# MCU_I3C0_COMMON_0_VBP2APB_WRAP_CORE_VBP_MIPI_I3C_MST register map
Vendor: Texas Instruments
Registers are 32-bit, read-write, reset 0x0 unless marked. A register's access mark holds for its fields unless they carry their own. Offsets are as the file gives them; [hi:lo] are bit positions; {n}, {i} and the like mark numbered series.

## MCU_I3C0_COMMON_0_VBP2APB_WRAP_CORE_VBP_MIPI_I3C_MST (part 2 of 2)
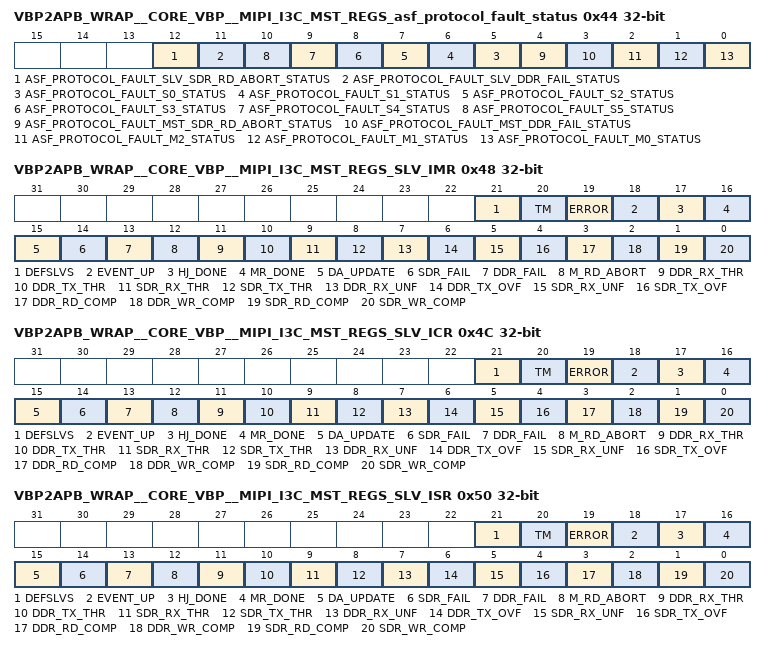
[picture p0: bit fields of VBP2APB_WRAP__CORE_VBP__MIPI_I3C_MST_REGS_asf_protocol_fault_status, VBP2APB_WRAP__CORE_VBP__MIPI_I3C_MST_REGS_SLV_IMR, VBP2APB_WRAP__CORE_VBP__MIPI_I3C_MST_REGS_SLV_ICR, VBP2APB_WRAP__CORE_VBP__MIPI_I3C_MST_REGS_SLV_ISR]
0x44 VBP2APB_WRAP__CORE_VBP__MIPI_I3C_MST_REGS_asf_protocol_fault_status access not given
  [12] ASF_PROTOCOL_FAULT_SLV_SDR_RD_ABORT_STATUS — Status bit for slv_sdr_rd_abort protocol fault. (access R/W1TC)
  [11] ASF_PROTOCOL_FAULT_SLV_DDR_FAIL_STATUS — Status bit for slv_ddr_fail protocol fault. (access R/W1TC)
  [n+5] ASF_PROTOCOL_FAULT_S{n}_STATUS (n=0..5) — Status bit for s{n} protocol fault. (access R/W1TC)
  [4] ASF_PROTOCOL_FAULT_MST_SDR_RD_ABORT_STATUS — Status bit for mst_sdr_rd_abort protocol fault. (access R/W1TC)
  [3] ASF_PROTOCOL_FAULT_MST_DDR_FAIL_STATUS — Status bit for mst_ddr_fail protocol fault. (access R/W1TC)
  [2] ASF_PROTOCOL_FAULT_M2_STATUS — Status bit for m2 protocol fault. (access R/W1TC)
  [1] ASF_PROTOCOL_FAULT_M1_STATUS — Status bit for m1 protocol fault. (access R/W1TC)
  [0] ASF_PROTOCOL_FAULT_M0_STATUS — Status bit for m0 protocol fault. (access R/W1TC)
0x48 VBP2APB_WRAP__CORE_VBP__MIPI_I3C_MST_REGS_SLV_IMR ro
  [21] DEFSLVS — DEFSLVS interrupt Mask.
  [20] TM — TM interrupt Mask.
  [19] ERROR — ERROR interrupt Mask.
  [18] EVENT_UP — EVENT_UP interrupt Mask.
  [17] HJ_DONE — HJ_DONE interrupt Mask.
  [16] MR_DONE — MR_DONE interrupt Mask.
  [15] DA_UPDATE — DA_UPDATE interrupt Mask.
  [14] SDR_FAIL — SDR_FAIL interrupt Mask
  [13] DDR_FAIL — DDR_FAIL interrupt Mask
  [12] M_RD_ABORT — M_RD_ABORT interrupt Mask.
  [11] DDR_RX_THR — DDR_RX_THR interrupt Mask.
  [10] DDR_TX_THR — DDR_TX_THR interrupt Mask.
  [9] SDR_RX_THR — SDR_RX_THR interrupt Mask.
  [8] SDR_TX_THR — SDR_TX_THR interrupt Mask.
  [7] DDR_RX_UNF — DDR_RX_UNF interrupt Mask.
  [6] DDR_TX_OVF — DDR_TX_OVF interrupt Mask.
  [5] SDR_RX_UNF — SDR_RX_UNF interrupt Mask.
  [4] SDR_TX_OVF — SDR_TX_OVF interrupt Mask.
  [3] DDR_RD_COMP — DDR_RD_COMP interrupt Mask.
  [2] DDR_WR_COMP — DDR_WR_COMP interrupt Mask.
  [1] SDR_RD_COMP — SDR_RD_COMP interrupt Mask.
  [0] SDR_WR_COMP — SDR_WR_COMP interrupt Mask.
0x4C VBP2APB_WRAP__CORE_VBP__MIPI_I3C_MST_REGS_SLV_ICR wo
  [21] DEFSLVS — DEFSLVS interrupt Clear.
  [20] TM — TM interrupt Clear.
  [19] ERROR — ERROR interrupt Clear.
  [18] EVENT_UP — EVENT_UP interrupt Clear.
  [17] HJ_DONE — HJ_DONE interrupt Clear.
  [16] MR_DONE — MR_DONE interrupt Clear.
  [15] DA_UPDATE — DA_UPDATE interrupt Clear.
  [14] SDR_FAIL — SDR_FAIL interrupt Clear.
  [13] DDR_FAIL — DDR_FAIL interrupt Clear.
  [12] M_RD_ABORT — M_RD_ABORT interrupt Clear.
  [11] DDR_RX_THR — DDR_RX_THR interrupt Clear.
  [10] DDR_TX_THR — DDR_TX_THR interrupt Clear.
  [9] SDR_RX_THR — SDR_RX_THR interrupt Clear.
  [8] SDR_TX_THR — SDR_TX_THR interrupt Clear.
  [7] DDR_RX_UNF — DDR_RX_UNF interrupt Clear.
  [6] DDR_TX_OVF — DDR_TX_OVF interrupt Clear.
  [5] SDR_RX_UNF — SDR_RX_UNF interrupt Clear.
  [4] SDR_TX_OVF — SDR_TX_OVF interrupt Clear.
  [3] DDR_RD_COMP — DDR_RD_COMP interrupt Clear.
  [2] DDR_WR_COMP — DDR_WR_COMP interrupt Clear.
  [1] SDR_RD_COMP — SDR_RD_COMP interrupt Clear.
  [0] SDR_WR_COMP — SDR_WR_COMP interrupt Clear.
0x50 VBP2APB_WRAP__CORE_VBP__MIPI_I3C_MST_REGS_SLV_ISR ro
  [21] DEFSLVS — This interrupt is triggered whenever I3C-Slave DEFSLVS CCC command is received.
  [20] TM — This interrupt is triggered whenever I3C-Slave is not in Test Mode and ENTTM CCC requests to enter general Test Mode.
  [19] ERROR — This event is triggered whenever SDR Error is detected - applicable for S0, S1, S2, S4 and S5 Errors from MIPI spec.
  [18] EVENT_UP — This event is triggered whenever DISEC CCC or ENEC CCC is received.
  [17] HJ_DONE — This event is triggered whenever Hot-Join request is completed.
  [16] MR_DONE — This event is triggered whenever Mastership Request is completed.
  [15] DA_UPDATE — This event is triggered whenever Dynamic Address of the device has been updated.
  [14] SDR_FAIL — This event is triggered whenever fail event during SDR transfer is detected [applicable for Private Write transfers only].
  [13] DDR_FAIL — This event is triggered whenever fail event during DDR transfer is detected.
  [12] M_RD_ABORT — Read Transfer Aborted by Master.
  [11] DDR_RX_THR — Slave DDR Rx DATA Buffer Threshold. It is set when the number of words in the Slave DDR Rx DATA Buffer reaches value programmed in SLV_DDR_TX_RX_THR_CTRL.slv_ddr_rx_thr field.
  [10] DDR_TX_THR — Slave DDR Tx DATA Buffer Threshold. It is set when the number of words in the Slave DDR Tx DATA Buffer reaches value programmed in SLV_DDR_TX_RX_THR_CTRL.slv_ddr_tx_thr field.
  [9] SDR_RX_THR — Rx DATA Buffer Threshold. It is set when the number of bytes in the Rx DATA Buffer reaches value programmed in TX_RX_THR_CTRL.rx_thr field.
  [8] SDR_TX_THR — Tx DATA Buffer Threshold. It is set when the number of bytes in the Tx DATA Buffer reaches value programmed in TX_RX_THR_CTRL.tx_thr field.
  [7] DDR_RX_UNF — Slave DDR Rx DATA Buffer Underflow. Set if host attempts to read from the empty Slave Rx DATA Buffer.
  [6] DDR_TX_OVF — Slave DDR Tx DATA Buffer Overflow. Set if host attepmts to write to Slvave DDR Tx DATA Buffer which is already full.
  [5] SDR_RX_UNF — Rx DATA Buffer Underflow. Set if host attempts to read from the empty Rx DATA Buffer.
  [4] SDR_TX_OVF — Tx DATA Buffer Overflow. Set if host attempts to write to Tx DATA Buffer which is already full.
  [3] DDR_RD_COMP — This bit is set whenever the Slave terminates the DDR Read transfer.
  [2] DDR_WR_COMP — This bit is set whenever the Master terminates the DDR Write transfer.
  [1] SDR_RD_COMP — This bit is set whenever the Slave terminates the SDR Private Read transfer.
  [0] SDR_WR_COMP — This bit is set whenever the Master terminates the SDR Private Write transfer.
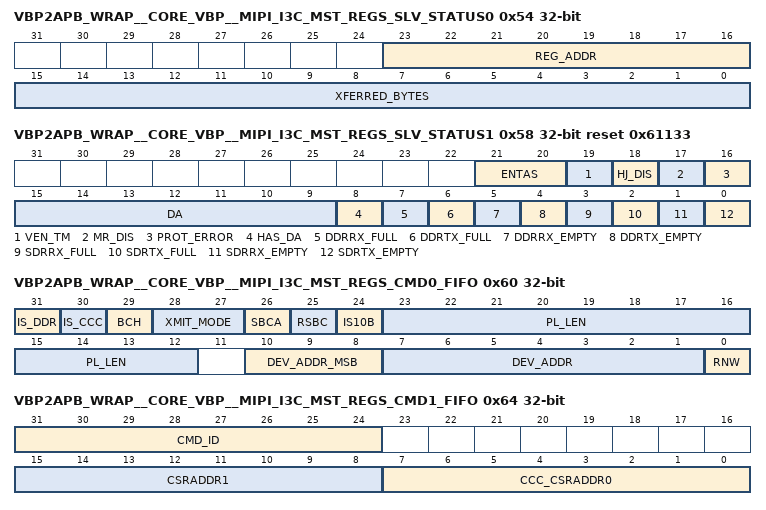
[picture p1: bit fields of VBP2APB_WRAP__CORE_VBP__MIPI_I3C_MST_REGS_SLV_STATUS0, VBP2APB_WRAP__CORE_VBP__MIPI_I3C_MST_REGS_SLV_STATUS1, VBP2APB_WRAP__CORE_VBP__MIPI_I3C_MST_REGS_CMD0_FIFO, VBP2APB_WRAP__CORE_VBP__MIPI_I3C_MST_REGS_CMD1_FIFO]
0x54 VBP2APB_WRAP__CORE_VBP__MIPI_I3C_MST_REGS_SLV_STATUS0 ro
  [23:16] REG_ADDR — Private Read/Write Address.
  [15:0] XFERRED_BYTES — Number of transferred bytes in SDR transactions.
0x58 VBP2APB_WRAP__CORE_VBP__MIPI_I3C_MST_REGS_SLV_STATUS1 ro reset 0x61133
  [21:20] ENTAS — Bits that indicate current Activity State. It is updated based on ENTASx CCC [broadcast or direct], by default is set to 2'b00.
  [19] VEN_TM — Vendor Test Mode. This bit is set whenever ENTTM CCC requests to enter general Test Mode. It remains HIGH until reception of another ENTTM CCC with different value.
  [18] HJ_DIS — Hot-Join Request is Disabled. This bit is set whenever HJ request is disabled by Current I3C-Master using DISEC CCC.
  [17] MR_DIS — Mastership Request is Disabled. This bit is set whenever MR request is disabled by Current I3C-Master using DISEC CCC.
  [16] PROT_ERROR — Protocol Error Condition Indicator. This bit is set whenever SDR error condition is detected by I3C-Master operating in Slave mode. It remains High until detection of recovery pattern.
  [15:9] DA — Current Slave Dynamic Address. Irrelevant if SLV_STATUS1.has_da bit is Low.
  [8] HAS_DA — This bit is set whenever Slave has Dynamic Address assigned. Tied HIGH when controller operates as Main Master device class.
  [7] DDRRX_FULL — This bit is set whenever Slave DDR Rx DATA Buffer is full.
  [6] DDRTX_FULL — This bit is set whenever Slave DDR Tx DATA Buffer is full.
  [5] DDRRX_EMPTY — This bit is set whenever Slave DDR Rx DATA Buffer is empty.
  [4] DDRTX_EMPTY — This bit is set whenever Slave DDR Tx DATA Buffer is empty.
  [3] SDRRX_FULL — This bit is set whenever Rx DATA Buffer is full.
  [2] SDRTX_FULL — This bit is set whenever Tx DATA Buffer is full.
  [1] SDRRX_EMPTY — This bit is set whenever Rx DATA Buffer is empty.
  [0] SDRTX_EMPTY — This bit is set whenever Tx DATA Buffer is empty.
0x60 VBP2APB_WRAP__CORE_VBP__MIPI_I3C_MST_REGS_CMD0_FIFO wo
  [31] IS_DDR — IS_DDR - DDR command. Enables DDR mode of transfer. 0 - SDR mode 1 - DDR mode, note that ENTHDR-DDR CCC should precede any commands with DDR mode enabled.
  [30] IS_CCC — IsCCC. Denotes whether it is a CCC or generic command. 0 - generic command 1 - CCC command
  [29] BCH — BCH - Broadcast Header. Defines whether command will includes broadcast address header [0x7E] or not. Implicitly set for CCC commands. 0 - broadcast header disabled 1 - broadcast header enabled
  [28:27] XMIT_MODE — Defines transfer modes for I3C SDR private read/write commands [not CCC], the following options are available: 00 - burst [byte-by-byte] transfer with static register sub-address. Send static sub-address followed by data bytes only. 01 - single data byte transfers with auto incremented register sub-addressing. Each data byte is followed by repeated start condition and slave's sub-address is inremented explicitly. 10 - single data byte transfers without auto incremented register sub-addressing. Each data byte is followed by repeated start condition, register sub-address as in CMD descriptor for all transactions. 11 - burst [byte-by-byte] transfer without register sub-addressing, i.e. first data byte after the DA/SA is payload byte acquired from Tx DATA buffer.
  [26] SBCA — SBCA - Sixteen Bits CSR Addressing. Defines the CSR addressing mode for I3C private commands only. 0 - normal CSR addressing mode [8-bit] - ADDR0_7 - ADDR0_0 1 - extended CSR addressing mode [16-bit] - ADDR0_7 - ADDR0_0 and ADDR1_7 - ADDR1_0
  [25] RSBC — RSBC - Repeated Start Between Commands. When this bit is set then between commands he repeated start condition is issued instead stop condition. It is only applicable when there is more than one command is in the command queue and next command is for Slave device of same type. The stop condition will be generated regardless of RSCB bit value for the following scenarios: - current command is the last command in the command queue - next command has invalid DA/SA - immediate command comes through
  [24] IS10B — Is10B - Normal/Extended Address. Defines the addressing mode, applicable only for legacy I2C messaging. 0 - normal addressing mode [7-bit] - ID6-ID0 1 - extended addressing mode [10-bit] - ID10B2-ID10B0 and ID6-ID0
  [23:12] PL_LEN — PL_LEN - Payload Length, defines number of bytes to be sent for particular CCC or generic R/Q command. Supports up to 4095 bytes.
  [10:8] DEV_ADDR_MSB — DEV_ADDR_MSB - legacy I2C Extended Address. The 3 MSB bits of legacy I2C 10-bit address. Applicable only if Is_10B is set for I2C legacy transfers.
  [7:1] DEV_ADDR — DEV_ADDR - Static/Dynamic slave Address. Correspond to a given slave Dynamic Address and Static Address. For CCC is applicable only when it is direct CCC command. For broadcast CCC this field is ignored.
  [0] RNW — RnW - Read no Write. Defines the direction of transfer, for broadcast CCC this field is ignored. 0 - Write Transfer 1 - Read Transfer
0x64 VBP2APB_WRAP__CORE_VBP__MIPI_I3C_MST_REGS_CMD1_FIFO wo
  [31:24] CMD_ID — CMD_ID - command identifier.
  [15:8] CSRADDR1 — CSR ADDR1 - second byte of the CSR address in 16-bit addressing mode. Applicable only when 16-bit addressing mode is used and for private commands [non CCC commands].
  [7:0] CCC_CSRADDR0 — CCC/CSR ADDR0 - CCC or CSR Address. Meaning of this field depends on bit 30 [IsCCC] of Command Word0. - When is_ccc is set to '0' then this field holds address of slave CSR. When 16-bit addressing is used, then it is the first byte of the CSR address. - When is ccc is set to '1' then this field holds code of CCC.
0x68 VBP2APB_WRAP__CORE_VBP__MIPI_I3C_MST_REGS_TX_FIFO wo
  [31:0] DATA — Tx DATA payload.
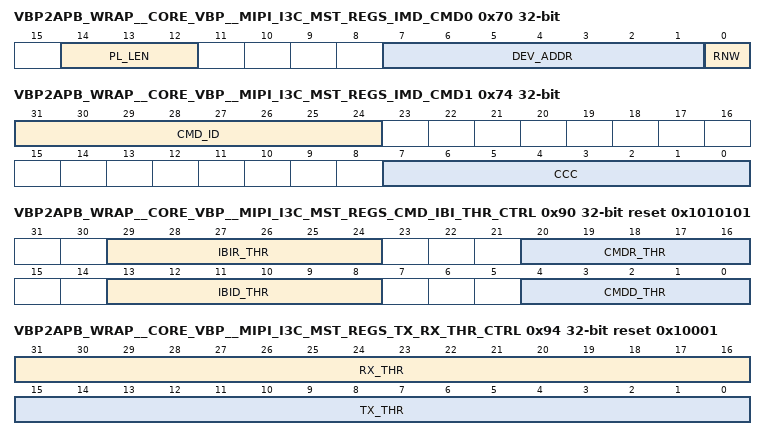
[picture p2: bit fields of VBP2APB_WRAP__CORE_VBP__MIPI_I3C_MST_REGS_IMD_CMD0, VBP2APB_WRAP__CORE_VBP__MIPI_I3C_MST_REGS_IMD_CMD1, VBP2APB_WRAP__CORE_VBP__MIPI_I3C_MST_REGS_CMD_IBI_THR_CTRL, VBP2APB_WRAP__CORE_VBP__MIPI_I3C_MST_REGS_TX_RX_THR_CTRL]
0x70 VBP2APB_WRAP__CORE_VBP__MIPI_I3C_MST_REGS_IMD_CMD0 wo
  [14:12] PL_LEN — PL_LEN - Payload Length, defines number of bytes to be send for particular CCC or generic R/W command. Supports up to 4 bytes.
  [7:1] DEV_ADDR — DEV_ADDR - Static/Dynamic slave Address. Correspond to a given slave Dynamic Address and Static Address. For CCC is applicable only when it is direct CCC command. For broadcast CCC this field is ignored.
  [0] RNW — RnW - Read not Write. Defines the direction of transfer, for broadcast CCC this field is ignored. 0 - Write Transfer 1 - Read Transfer
0x74 VBP2APB_WRAP__CORE_VBP__MIPI_I3C_MST_REGS_IMD_CMD1 wo
  [31:24] CMD_ID — CMD_ID - command identifier.
  [7:0] CCC — CCC Code - field holds code of CCC message.
0x78 VBP2APB_WRAP__CORE_VBP__MIPI_I3C_MST_REGS_IMD_DATA
  [31:0] DATA — Tx DATA payload [it's not a FIFO, supports up to 4 bytes only].
0x80 VBP2APB_WRAP__CORE_VBP__MIPI_I3C_MST_REGS_RX_FIFO ro
  [31:0] DATA — Rx DATA payload.
0x84 VBP2APB_WRAP__CORE_VBP__MIPI_I3C_MST_REGS_IBI_DATA_FIFO ro
  [31:0] DATA — IBI DATA payload.
0x88 VBP2APB_WRAP__CORE_VBP__MIPI_I3C_MST_REGS_SLV_DDR_TX_FIFO wo
  [19:0] DDR_SLAVE_TX_DATA_FIFO — DDR Tx DATA payload [with meta-data, e.g. preamble/parity].
0x8C VBP2APB_WRAP__CORE_VBP__MIPI_I3C_MST_REGS_SLV_DDR_RX_FIFO ro
  [19:0] DDR_SLAVE_RX_DATA_FIFO — DDR Rx DATA payload [with meta-data, e.g. preamble/parity].
0x90 VBP2APB_WRAP__CORE_VBP__MIPI_I3C_MST_REGS_CMD_IBI_THR_CTRL reset 0x1010101
  [29:24] IBIR_THR — Threshold configuration value for IBI Response Queue.
  [20:16] CMDR_THR — Threshold configuration value for Command Response Queue.
  [13:8] IBID_THR — Threshold configuration value for IBI DATA Buffer.
  [4:0] CMDD_THR — Threshold configuration value for Command Queue.
0x94 VBP2APB_WRAP__CORE_VBP__MIPI_I3C_MST_REGS_TX_RX_THR_CTRL reset 0x10001
  [31:16] RX_THR — Threshold configuration value for Rx Data memory block
  [15:0] TX_THR — Threshold configuration value for Tx Data memory block
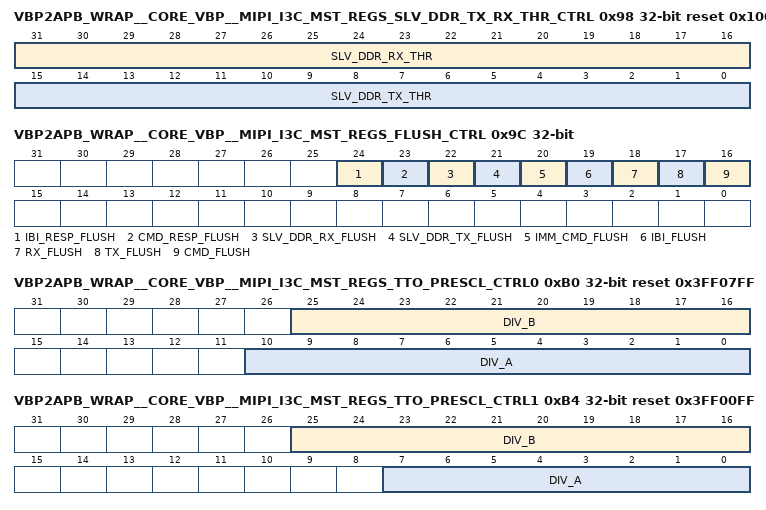
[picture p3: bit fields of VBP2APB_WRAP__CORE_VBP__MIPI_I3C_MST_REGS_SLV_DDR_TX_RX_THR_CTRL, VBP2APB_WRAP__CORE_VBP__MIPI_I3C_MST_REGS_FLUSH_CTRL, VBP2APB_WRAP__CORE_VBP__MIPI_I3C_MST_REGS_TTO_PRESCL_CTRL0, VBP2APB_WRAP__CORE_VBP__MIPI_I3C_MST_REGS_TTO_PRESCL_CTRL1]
0x98 VBP2APB_WRAP__CORE_VBP__MIPI_I3C_MST_REGS_SLV_DDR_TX_RX_THR_CTRL reset 0x10001
  [31:16] SLV_DDR_RX_THR — Threshold configuration value for Slave DDR Rx DATA buffer.
  [15:0] SLV_DDR_TX_THR — Threshold configuration value for Slave DDR Tx DATA buffer.
0x9C VBP2APB_WRAP__CORE_VBP__MIPI_I3C_MST_REGS_FLUSH_CTRL wo
  [24] IBI_RESP_FLUSH — When asserted while controller is disabled, the IBI Response Queue read/write pointers will be set to 0, effectively makes the buffer empty. Self-cleared control bit.
  [23] CMD_RESP_FLUSH — When asserted while controller is disabled, the Command Response Queue read/write pointers will be set to 0, effectively makes the buffer empty. Self-cleared control bit.
  [22] SLV_DDR_RX_FLUSH — When asserted while controller is disabled, the Slave DDR Rx DATA Buffer read/write pointers will be set to 0, effectively makes the buffer empty. Self-cleared control bit.
  [21] SLV_DDR_TX_FLUSH — When asserted while controller is disabled, the Slave DDR Tx DATA Buffer read/write pointers will be set to 0, effectively makes the buffer empty. Self-cleared control bit.
  [20] IMM_CMD_FLUSH — When asserted while controller is disabled, the Immediate Commadn/DATA registers will be cleared and their empty flag will be asserted. Self-cleared control bit.
  [19] IBI_FLUSH — When asserted while controller is disabled, the IBI DATA Buffer read/write pointers will be set to 0, effectively makes the buffer empty. Self-cleared control bit.
  [18] RX_FLUSH — When asserted while controller is disabled, the Rx DATA Buffer read/write pointers will be set to 0, effectively makes the buffer empty. Self-cleared control bit.. Self-cleared control bit.
  [17] TX_FLUSH — When asserted while controller is disabled, the Tx DATA Buffer read/write pointers will be set to 0, effectively makes the buffer empty. Self-cleared control bit.
  [16] CMD_FLUSH — When asserted while controller is disabled, the Command Buffer read/write pointers will be set to 0, effectively makes the buffer empty. Self-cleared control bit.
0xB0 VBP2APB_WRAP__CORE_VBP__MIPI_I3C_MST_REGS_TTO_PRESCL_CTRL0 reset 0x3FF07FF
  [25:16] DIV_B — Divider B
  [10:0] DIV_A — Divider A
0xB4 VBP2APB_WRAP__CORE_VBP__MIPI_I3C_MST_REGS_TTO_PRESCL_CTRL1 reset 0x3FF00FF
  [25:16] DIV_B — Divider B
  [7:0] DIV_A — Divider A
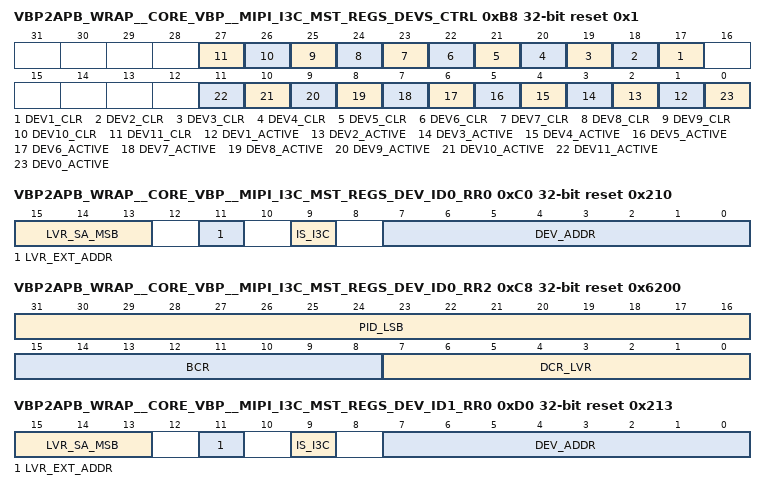
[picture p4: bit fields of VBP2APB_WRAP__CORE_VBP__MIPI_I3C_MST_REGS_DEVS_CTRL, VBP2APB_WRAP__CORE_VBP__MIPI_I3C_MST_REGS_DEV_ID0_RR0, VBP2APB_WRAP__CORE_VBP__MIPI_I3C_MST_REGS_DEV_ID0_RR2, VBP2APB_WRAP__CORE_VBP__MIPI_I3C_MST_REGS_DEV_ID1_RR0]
0xB8 VBP2APB_WRAP__CORE_VBP__MIPI_I3C_MST_REGS_DEVS_CTRL access per field reset 0x1
  [n+16] DEV{n}_CLR wo (n=1..11) — Clear contents of DevID{n} retaining registers. Self-cleared bit.
  [n] DEV{n}_ACTIVE rw (n=1..11) — DevID{n} is active - has either valid DA or SA.
  [0] DEV0_ACTIVE ro — DevID0 is active - has either valid DA or SA.
0xC0 VBP2APB_WRAP__CORE_VBP__MIPI_I3C_MST_REGS_DEV_ID0_RR0 access per field reset 0x210
  [15:13] LVR_SA_MSB rw — MSB bits of Legacy I2C Device with 10-bit addressing.
  [11] LVR_EXT_ADDR rw — Device 0 Address mode used: 0 - 7-bit addressing - applicable for I3C and I2C devices. 1 - 10-bit addressing - applicable only for I2C devices with 10-bit extended address. NOTE: Invalid setting when Device0_RR0.is_i3c=1
  [9] IS_I3C ro — Device 0 I3C mode Operation 1 Yes 0 No
  [7:0] DEV_ADDR rw — Device 0 Slave Dynamic [Static/Legacy] Address bits 7:1 bit 0 - parity XOR check -> ~XOR[dev_addr[7:1]].
0xC4 VBP2APB_WRAP__CORE_VBP__MIPI_I3C_MST_REGS_DEV_ID0_RR1 reset 0x2040000
  [31:0] PID_MSB — Device 0 48 to 16 Dev ID bits
0xC8 VBP2APB_WRAP__CORE_VBP__MIPI_I3C_MST_REGS_DEV_ID0_RR2 reset 0x6200
  [31:16] PID_LSB — Device 0 15 to 0 Dev ID bits
  [15:8] BCR — Device 0 BCR register
  [7:0] DCR_LVR — Device 0 DCR [if I3C device] or LVR [if I2C device] register Decoding if used as DCR: Bits[7:0]: 255 available codes for describing the type of sensor, or Device; Decoding if used as LVR: Bits [7:4]: Device 0 LVR Code: 15 available codes for describing the Device capabilities and function on the sensors' system Bits [3:3]: Device 0 LVR Slave operation mode: 1'b0 FM mode 1'b1 FM+ mode Bits [2:0]: Device 0 LVR Index: 3'b000 Index 0 3'b001 Index 1 3'b010 Index 2 3'b011 Index 3 [Reserved] 3'b100 Index 4 [Reserved] 3'b101 Index 5 [Reserved] 3'b110 Index 6 [Reserved] 3'b111 Index 7 [Reserved]
0xD0 VBP2APB_WRAP__CORE_VBP__MIPI_I3C_MST_REGS_DEV_ID1_RR0 reset 0x213
  [15:13] LVR_SA_MSB — MSB bits of Legacy I2C Device with 10-bit addressing.
  [11] LVR_EXT_ADDR — Device 1 Address mode used: 0 - 7-bit addressing - applicable for I3C and I2C devices. 1 - 10-bit addressing - applicable only for I2C devices with 10-bit extended address. NOTE: Invalid setting when Device1_RR0.is_i3c=1
  [9] IS_I3C — Device 1 I3C mode Operation 1 Yes 0 No
  [7:0] DEV_ADDR — Device 1 Slave Dynamic [Static/Legacy] Address bits 7:1 bit 0 - parity XOR check -> ~XOR[dev_addr[7:1]].
{0xC4+0x10*i} VBP2APB_WRAP__CORE_VBP__MIPI_I3C_MST_REGS_DEV_ID{i}_RR1 (i=1..11)
  [31:0] PID_MSB — Device {i} 48 to 16 Dev ID bits
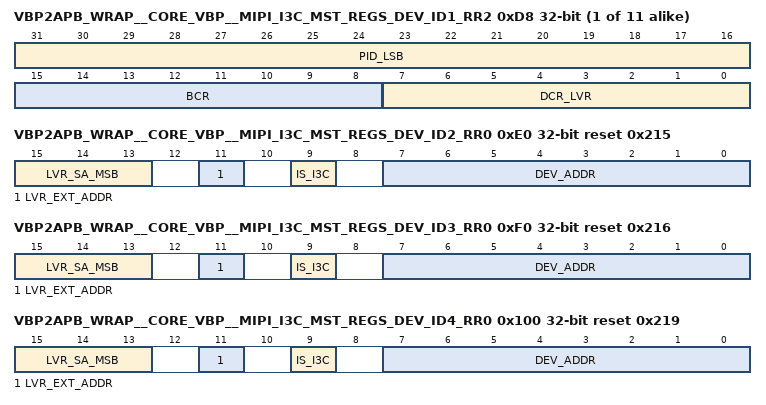
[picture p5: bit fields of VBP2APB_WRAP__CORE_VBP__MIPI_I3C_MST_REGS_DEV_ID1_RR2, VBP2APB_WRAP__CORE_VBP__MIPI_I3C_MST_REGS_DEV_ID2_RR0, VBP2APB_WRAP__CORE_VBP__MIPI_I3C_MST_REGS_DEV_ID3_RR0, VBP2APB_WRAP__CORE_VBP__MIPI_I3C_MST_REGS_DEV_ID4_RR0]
{0xC8+0x10*i} VBP2APB_WRAP__CORE_VBP__MIPI_I3C_MST_REGS_DEV_ID{i}_RR2 (i=1..11)
  [31:16] PID_LSB — Device {i} 15 to 0 Dev ID bits
  [15:8] BCR — Device {i} BCR register
  [7:0] DCR_LVR — Device {i} DCR [if I3C device] or LVR [if I2C device] register Decoding if used as DCR: Bits[7:0]: 255 available codes for describing the type of sensor, or Device; Decoding if used as LVR: Bits [7:4]: Device {i} LVR Code: 15 available codes for describing the Device capabilities and function on the sensors' system Bits [3:3]: Device {i} LVR Slave operation mode: 1'b0 FM mode 1'b1 FM+ mode Bits [2:0]: Device {i} LVR Index: 3'b000 Index 0 3'b001 Index 1 3'b010 Index 2 3'b011 Index 3 [Reserved] 3'b100 Index 4 [Reserved] 3'b101 Index 5 [Reserved] 3'b110 Index 6 [Reserved] 3'b111 Index 7 [Reserved]
0xE0 VBP2APB_WRAP__CORE_VBP__MIPI_I3C_MST_REGS_DEV_ID2_RR0 reset 0x215
  [15:13] LVR_SA_MSB — MSB bits of Legacy I2C Device with 10-bit addressing.
  [11] LVR_EXT_ADDR — Device 2 Address mode used: 0 - 7-bit addressing - applicable for I3C and I2C devices. 1 - 10-bit addressing - applicable only for I2C devices with 10-bit extended address. NOTE: Invalid setting when Device2_RR0.is_i3c=1
  [9] IS_I3C — Device 2 I3C mode Operation 1 Yes 0 No
  [7:0] DEV_ADDR — Device 2 Slave Dynamic [Static/Legacy] Address bits 7:1 bit 0 - parity XOR check -> ~XOR[dev_addr[7:1]].
0xF0 VBP2APB_WRAP__CORE_VBP__MIPI_I3C_MST_REGS_DEV_ID3_RR0 reset 0x216
  [15:13] LVR_SA_MSB — MSB bits of Legacy I2C Device with 10-bit addressing.
  [11] LVR_EXT_ADDR — Device 3 Address mode used: 0 - 7-bit addressing - applicable for I3C and I2C devices. 1 - 10-bit addressing - applicable only for I2C devices with 10-bit extended address. NOTE: Invalid setting when Device3_RR0.is_i3c=1
  [9] IS_I3C — Device 3 I3C mode Operation 1 Yes 0 No
  [7:0] DEV_ADDR — Device 3 Slave Dynamic [Static/Legacy] Address bits 7:1 bit 0 - parity XOR check -> ~XOR[dev_addr[7:1]].
0x100 VBP2APB_WRAP__CORE_VBP__MIPI_I3C_MST_REGS_DEV_ID4_RR0 reset 0x219
  [15:13] LVR_SA_MSB — MSB bits of Legacy I2C Device with 10-bit addressing.
  [11] LVR_EXT_ADDR — Device 4 Address mode used: 0 - 7-bit addressing - applicable for I3C and I2C devices. 1 - 10-bit addressing - applicable only for I2C devices with 10-bit extended address. NOTE: Invalid setting when Device4_RR0.is_i3c=1
  [9] IS_I3C — Device 4 I3C mode Operation 1 Yes 0 No
  [7:0] DEV_ADDR — Device 4 Slave Dynamic [Static/Legacy] Address bits 7:1 bit 0 - parity XOR check -> ~XOR[dev_addr[7:1]].
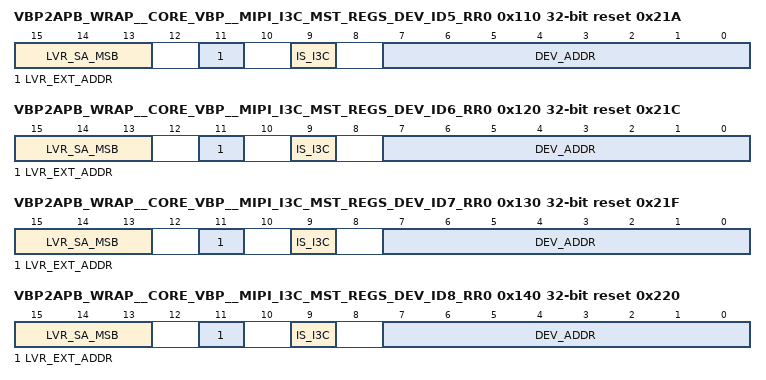
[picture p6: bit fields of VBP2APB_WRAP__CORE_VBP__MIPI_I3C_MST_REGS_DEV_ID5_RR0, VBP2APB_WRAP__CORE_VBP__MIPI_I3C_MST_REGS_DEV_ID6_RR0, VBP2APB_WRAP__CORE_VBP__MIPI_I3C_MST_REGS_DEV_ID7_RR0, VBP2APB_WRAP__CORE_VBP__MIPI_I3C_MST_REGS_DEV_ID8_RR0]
0x110 VBP2APB_WRAP__CORE_VBP__MIPI_I3C_MST_REGS_DEV_ID5_RR0 reset 0x21A
  [15:13] LVR_SA_MSB — MSB bits of Legacy I2C Device with 10-bit addressing.
  [11] LVR_EXT_ADDR — Device 5 Address mode used: 0 - 7-bit addressing - applicable for I3C and I2C devices. 1 - 10-bit addressing - applicable only for I2C devices with 10-bit extended address. NOTE: Invalid setting when Device5_RR0.is_i3c=1
  [9] IS_I3C — Device 5 I3C mode Operation 1 Yes 0 No
  [7:0] DEV_ADDR — Device 5 Slave Dynamic [Static/Legacy] Address bits 7:1 bit 0 - parity XOR check -> ~XOR[dev_addr[7:1]].
0x120 VBP2APB_WRAP__CORE_VBP__MIPI_I3C_MST_REGS_DEV_ID6_RR0 reset 0x21C
  [15:13] LVR_SA_MSB — MSB bits of Legacy I2C Device with 10-bit addressing.
  [11] LVR_EXT_ADDR — Device 6 Address mode used: 0 - 7-bit addressing - applicable for I3C and I2C devices. 1 - 10-bit addressing - applicable only for I2C devices with 10-bit extended address. NOTE: Invalid setting when Device6_RR0.is_i3c=1
  [9] IS_I3C — Device 6 I3C mode Operation 1 Yes 0 No
  [7:0] DEV_ADDR — Device 6 Slave Dynamic [Static/Legacy] Address bits 7:1 bit 0 - parity XOR check -> ~XOR[dev_addr[7:1]].
0x130 VBP2APB_WRAP__CORE_VBP__MIPI_I3C_MST_REGS_DEV_ID7_RR0 reset 0x21F
  [15:13] LVR_SA_MSB — MSB bits of Legacy I2C Device with 10-bit addressing.
  [11] LVR_EXT_ADDR — Device 7 Address mode used: 0 - 7-bit addressing - applicable for I3C and I2C devices. 1 - 10-bit addressing - applicable only for I2C devices with 10-bit extended address. NOTE: Invalid setting when Device7_RR0.is_i3c=1
  [9] IS_I3C — Device 7 I3C mode Operation 1 Yes 0 No
  [7:0] DEV_ADDR — Device 7 Slave Dynamic [Static/Legacy] Address bits 7:1 bit 0 - parity XOR check -> ~XOR[dev_addr[7:1]].
0x140 VBP2APB_WRAP__CORE_VBP__MIPI_I3C_MST_REGS_DEV_ID8_RR0 reset 0x220
  [15:13] LVR_SA_MSB — MSB bits of Legacy I2C Device with 10-bit addressing.
  [11] LVR_EXT_ADDR — Device 8 Address mode used: 0 - 7-bit addressing - applicable for I3C and I2C devices. 1 - 10-bit addressing - applicable only for I2C devices with 10-bit extended address. NOTE: Invalid setting when Device8_RR0.is_i3c=1
  [9] IS_I3C — Device 8 I3C mode Operation 1 Yes 0 No
  [7:0] DEV_ADDR — Device 8 Slave Dynamic [Static/Legacy] Address bits 7:1 bit 0 - parity XOR check -> ~XOR[dev_addr[7:1]].
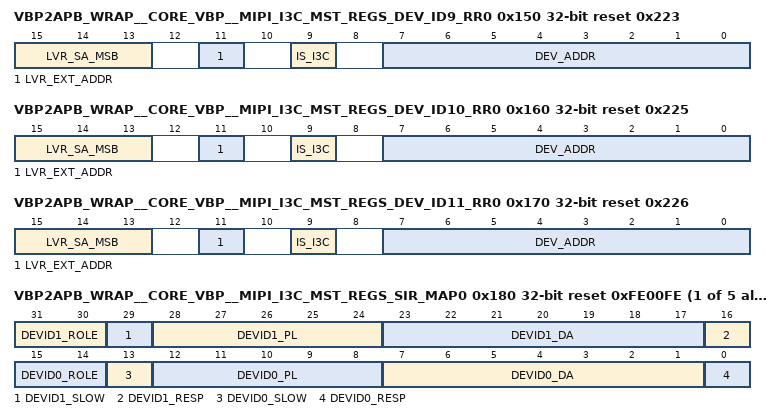
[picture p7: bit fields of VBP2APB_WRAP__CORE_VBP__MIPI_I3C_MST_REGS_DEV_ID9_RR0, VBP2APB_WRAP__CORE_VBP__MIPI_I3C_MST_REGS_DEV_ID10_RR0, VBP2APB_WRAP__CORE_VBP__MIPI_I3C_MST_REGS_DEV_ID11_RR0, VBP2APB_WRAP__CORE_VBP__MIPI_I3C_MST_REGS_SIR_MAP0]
0x150 VBP2APB_WRAP__CORE_VBP__MIPI_I3C_MST_REGS_DEV_ID9_RR0 reset 0x223
  [15:13] LVR_SA_MSB — MSB bits of Legacy I2C Device with 10-bit addressing.
  [11] LVR_EXT_ADDR — Device 9 Address mode used: 0 - 7-bit addressing - applicable for I3C and I2C devices. 1 - 10-bit addressing - applicable only for I2C devices with 10-bit extended address. NOTE: Invalid setting when Device9_RR0.is_i3c=1
  [9] IS_I3C — Device 9 I3C mode Operation 1 Yes 0 No
  [7:0] DEV_ADDR — Device 9 Slave Dynamic [Static/Legacy] Address bits 7:1 bit 0 - parity XOR check -> ~XOR[dev_addr[7:1]].
0x160 VBP2APB_WRAP__CORE_VBP__MIPI_I3C_MST_REGS_DEV_ID10_RR0 reset 0x225
  [15:13] LVR_SA_MSB — MSB bits of Legacy I2C Device with 10-bit addressing.
  [11] LVR_EXT_ADDR — Device 10 Address mode used: 0 - 7-bit addressing - applicable for I3C and I2C devices. 1 - 10-bit addressing - applicable only for I2C devices with 10-bit extended address. NOTE: Invalid setting when Device10_RR0.is_i3c=1
  [9] IS_I3C — Device 10 I3C mode Operation 1 Yes 0 No
  [7:0] DEV_ADDR — Device 10 Slave Dynamic [Static/Legacy] Address bits 7:1 bit 0 - parity XOR check -> ~XOR[dev_addr[7:1]].
0x170 VBP2APB_WRAP__CORE_VBP__MIPI_I3C_MST_REGS_DEV_ID11_RR0 reset 0x226
  [15:13] LVR_SA_MSB — MSB bits of Legacy I2C Device with 10-bit addressing.
  [11] LVR_EXT_ADDR — Device 11 Address mode used: 0 - 7-bit addressing - applicable for I3C and I2C devices. 1 - 10-bit addressing - applicable only for I2C devices with 10-bit extended address. NOTE: Invalid setting when Device11_RR0.is_i3c=1
  [9] IS_I3C — Device 11 I3C mode Operation 1 Yes 0 No
  [7:0] DEV_ADDR — Device 11 Slave Dynamic [Static/Legacy] Address bits 7:1 bit 0 - parity XOR check -> ~XOR[dev_addr[7:1]].
{0x180+4i} VBP2APB_WRAP__CORE_VBP__MIPI_I3C_MST_REGS_SIR_MAP{i} reset 0xFE00FE (i=0..4)
  [31:30] DEVID{2i+1}_ROLE — Slave-initiated request Device ID{2i} BCR role 2'b00 - Slave 2'b01 - Master/Secondary Master 2'b10 - Reserved 2'b11 - Reserved
  [29] DEVID{2i+1}_SLOW — Slave-initiated request Device ID{2i} Max Data Speed Limitation 0 - No limitation 1 - Limitation
  [28:24] DEVID{2i+1}_PL — Slave-initiated request Device ID{2i} payload length
  [23:17] DEVID{2i+1}_DA — Slave-initiated request Device ID{2i} DA
  [16] DEVID{2i+1}_RESP — Slave-initiated request Device ID{2i} Ack/Nack response 0 - NACK each request from this device. 1 - ACK each request from this device.
  [15:14] DEVID{2i}_ROLE — Slave-initiated request Device ID{2i} BCR role 2'b00 - Slave 2'b01 - Master/Secondary Master 2'b10 - Reserved 2'b11 - Reserved
  [13] DEVID{2i}_SLOW — Slave-initiated request Device ID{2i} Max Data Speed Limitation 0 - No limitation 1 - Limitation
  [12:8] DEVID{2i}_PL — Slave-initiated request Device ID{2i} payload length
  [7:1] DEVID{2i}_DA — Slave-initiated request Device ID{2i} DA
  [0] DEVID{2i}_RESP — Slave-initiated request Device ID{2i} Ack/Nack response 0 - NACK each request from this device. 1 - ACK each request from this device.
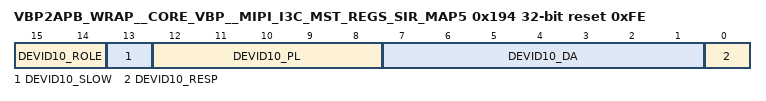
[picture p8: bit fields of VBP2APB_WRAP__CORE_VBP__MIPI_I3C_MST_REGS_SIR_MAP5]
0x194 VBP2APB_WRAP__CORE_VBP__MIPI_I3C_MST_REGS_SIR_MAP5 reset 0xFE
  [15:14] DEVID10_ROLE — Slave-initiated request Device ID10 BCR role 2'b00 - Slave 2'b01 - Master/Secondary Master 2'b10 - Reserved 2'b11 - Reserved
  [13] DEVID10_SLOW — Slave-initiated request Device ID10 Max Data Speed Limitation 0 - No limitation 1 - Limitation
  [12:8] DEVID10_PL — Slave-initiated request Device ID10 payload length
  [7:1] DEVID10_DA — Slave-initiated request Device ID10 DA
  [0] DEVID10_RESP — Slave-initiated request Device ID10 Ack/Nack response 0 - NACK each request from this device. 1 - ACK each request from this device.
0x1A0 VBP2APB_WRAP__CORE_VBP__MIPI_I3C_MST_REGS_GPIR_WORD0 ro
  [7:0] GPI0 — User Defined GPI Register 0
0x220 VBP2APB_WRAP__CORE_VBP__MIPI_I3C_MST_REGS_GPOR_WORD0 ro
  [7:0] GPO0 — User Defined GPO Register 0
